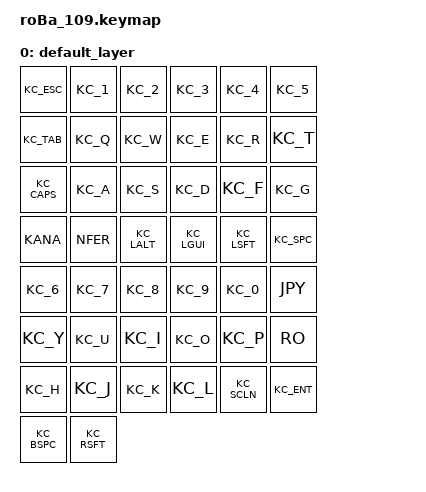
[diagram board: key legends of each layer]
/ {
    keymap {
        compatible = "zmk,keymap";

        default_layer {
            bindings = <
                // 左手（3親指）
                KC_ESC    KC_1      KC_2      KC_3      KC_4      KC_5
                KC_TAB    KC_Q      KC_W      KC_E      KC_R      KC_T
                KC_CAPS   KC_A      KC_S      KC_D      KC_F      KC_G
                KANA      NFER      KC_LALT   KC_LGUI   KC_LSFT   KC_SPC

                // 右手（親指2）
                KC_6      KC_7      KC_8      KC_9      KC_0      JPY
                KC_Y      KC_U      KC_I      KC_O      KC_P      RO
                KC_H      KC_J      KC_K      KC_L      KC_SCLN   KC_ENT
                KC_BSPC   KC_RSFT
            >;
        };
    };
};
 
